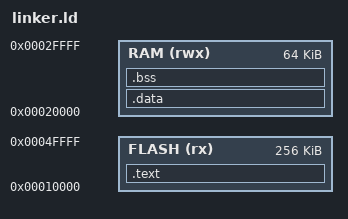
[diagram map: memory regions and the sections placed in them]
ENTRY(Reset_Handler)

MEMORY
{
    FLASH (rx)  : ORIGIN = 0x00010000, LENGTH = 256K
    RAM   (rwx) : ORIGIN = 0x00020000, LENGTH = 64K
}

_stack_top = ORIGIN(RAM) + LENGTH(RAM);

SECTIONS
{
    .text :
    {
        . = ALIGN(4);
        _svectors = .;
        KEEP(*(.vectors))
        *(.text*)
        *(.rodata*)
        . = ALIGN(4);
        _etext = .;
    } > FLASH

    .data : AT (_etext)
    {
        . = ALIGN(4);
        _sdata = .;
        *(.data*)
        . = ALIGN(4);
        _edata = .;
    } > RAM

    .bss :
    {
        . = ALIGN(4);
        _sbss = .;
        *(.bss*)
        *(COMMON)
        . = ALIGN(4);
        _ebss = .;
    } > RAM
}
